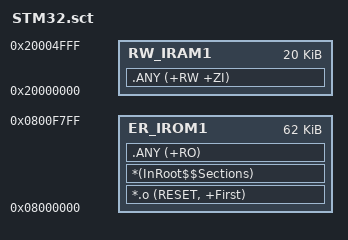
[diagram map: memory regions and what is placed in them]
; *** Scatter-Loading Description File generated by uVision ***
;
; Main Flash: 0x08000000 ~ 0x0800FFFF  = 0x80000 (64kb)
; SRAM      : 0x20000000 ~ 0x20010000  = 0x2800  (10kB)
; *************************************************************

LR_IROM1 0x08000000 0x00010000     ; load region size_region
{    
    ER_IROM1 0x08000000 0xF800     ; load address = execution address
    {
        *.o (RESET, +First)
        *(InRoot$$Sections)
        .ANY (+RO)
    }
    ;ER_DATABASE 0x0800F800 0x800  ; last two page used for parameter
    ;{
        ;*.o (SECION_DATABASE)
        ;*.o (SECION_VERSION)
    ;}
    RW_IRAM1 0x20000000 0x5000     ; RW data
    {
        .ANY (+RW +ZI)
    }
}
